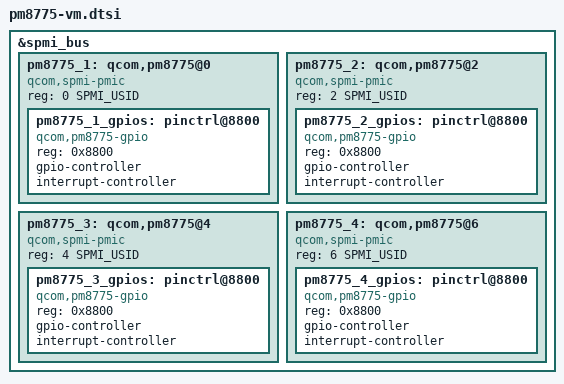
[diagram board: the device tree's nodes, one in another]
#include <dt-bindings/spmi/spmi.h>

&spmi_bus {
	#address-cells = <2>;
	#size-cells = <0>;

	pm8775_1: qcom,pm8775@0 {
		compatible = "qcom,spmi-pmic";
		reg = <0 SPMI_USID>;
		#address-cells = <1>;
		#size-cells = <0>;

		pm8775_1_gpios: pinctrl@8800 {
			compatible = "qcom,pm8775-gpio";
			reg = <0x8800>;
			gpio-controller;
			#gpio-cells = <2>;
			interrupt-controller;
			#interrupt-cells = <2>;
		};
	};

	/* below definitions are for the second instance of pm8775 */
	pm8775_2: qcom,pm8775@2 {
		compatible = "qcom,spmi-pmic";
		reg = <2 SPMI_USID>;
		#address-cells = <1>;
		#size-cells = <0>;

		pm8775_2_gpios: pinctrl@8800 {
			compatible = "qcom,pm8775-gpio";
			reg = <0x8800>;
			gpio-controller;
			#gpio-cells = <2>;
			interrupt-controller;
			#interrupt-cells = <2>;
		};
	};

	/* below definitions are for the third instance of pm8775 */
	pm8775_3: qcom,pm8775@4 {
		compatible = "qcom,spmi-pmic";
		reg = <4 SPMI_USID>;
		#address-cells = <1>;
		#size-cells = <0>;

		pm8775_3_gpios: pinctrl@8800 {
			compatible = "qcom,pm8775-gpio";
			reg = <0x8800>;
			gpio-controller;
			#gpio-cells = <2>;
			interrupt-controller;
			#interrupt-cells = <2>;
		};
	};

	/* below definitions are for the fourth instance of pm8775 */
	pm8775_4: qcom,pm8775@6 {
		compatible = "qcom,spmi-pmic";
		reg = <6 SPMI_USID>;
		#address-cells = <1>;
		#size-cells = <0>;

		pm8775_4_gpios: pinctrl@8800 {
			compatible = "qcom,pm8775-gpio";
			reg = <0x8800>;
			gpio-controller;
			#gpio-cells = <2>;
			interrupt-controller;
			#interrupt-cells = <2>;
		};
	};
};
